# DSS_DSI0_DSI_WRAP_MMR_VBUSP_CFG_DSI_WRAP register map
Vendor: Texas Instruments
Peripheral module from a debugger description file (folder J7ES).
Registers are 32-bit, read-only, reset 0x0 unless marked. A register's access mark holds for its fields unless they carry their own. Offsets are as the file gives them; lines under a group give offsets from that group; [hi:lo] are bit positions; {n}, {i} and the like mark numbered series; 'fields as' and 'values as' point back to an identical list; <NAME> marks a mode.

## DSS_DSI0_DSI_WRAP_MMR_VBUSP_CFG_DSI_WRAP
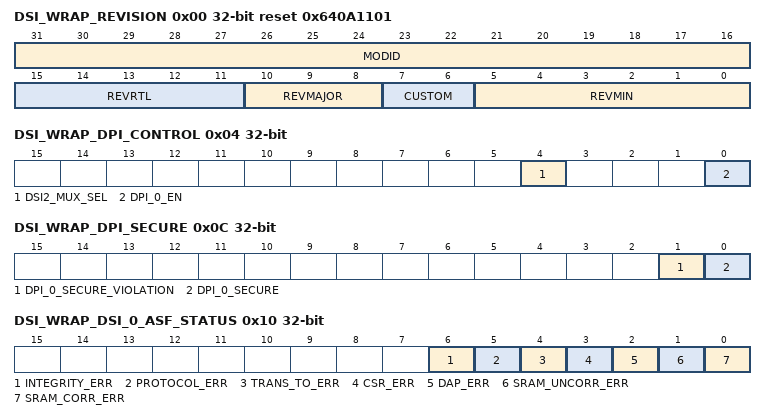
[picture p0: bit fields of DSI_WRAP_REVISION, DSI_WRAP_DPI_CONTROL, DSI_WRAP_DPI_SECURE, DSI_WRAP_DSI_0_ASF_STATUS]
0x00 DSI_WRAP_REVISION reset 0x640A1101 — The REVISION register contains the DSI revision number and PID
  [31:16] MODID — Module ID Field
  [15:11] REVRTL — RTL Revision
  [10:8] REVMAJOR — Major Revision
  [7:6] CUSTOM
  [5:0] REVMIN — Minor Revision
0x04 DSI_WRAP_DPI_CONTROL rw — Controls the DPI Video Input ports of the DSI Wrapper
  [4] DSI2_MUX_SEL — Select between DPI-1 and DPI-2 to drive the DPI input of DSITX2
  [0] DPI_0_EN — Enable for DPI-0 input
0x08 DSI_WRAP_DSC_CONTROL size not given access not given reset not defined — Controls the DSC Encoder for DSI
0x0C DSI_WRAP_DPI_SECURE access not given — Controls the DPI Video Input ports SECURE settings
  [1] DPI_0_SECURE_VIOLATION — SECURE VIOLATION status for DPI-0 input. (access RW1C)
  [0] DPI_0_SECURE rw — SECURE bit for DPI-0 input
0x10 DSI_WRAP_DSI_0_ASF_STATUS — ASF Status
  [6] INTEGRITY_ERR, [5] PROTOCOL_ERR, [4] TRANS_TO_ERR, [3] CSR_ERR, [2] DAP_ERR, [1] SRAM_UNCORR_ERR, [0] SRAM_CORR_ERR
